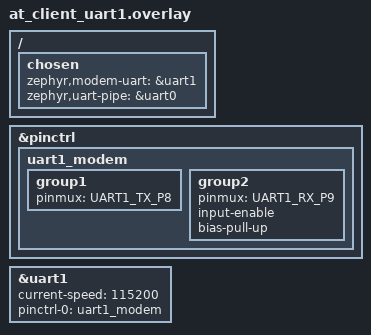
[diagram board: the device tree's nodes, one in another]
/* SPDX-License-Identifier: Apache-2.0 OR MIT */
/*
 * samples/drivers/modem/at_client bridges the console (uart0) to the modem
 * UART, which it takes from the zephyr,modem-uart chosen node: uart1 on the
 * straight-through pins, DUT TX GP8 and RX GP9, as the rig's uart1 images
 * (devices/neo_m8n/test/dut/uart1/rp2.overlay). RX is pulled up so the line
 * idles high before the harness attaches the modem part.
 */
/ {
	chosen {
		zephyr,modem-uart = &uart1;
		zephyr,uart-pipe = &uart0;
	};
};

&pinctrl {
	uart1_modem: uart1_modem {
		group1 {
			pinmux = <UART1_TX_P8>;
		};
		group2 {
			pinmux = <UART1_RX_P9>;
			input-enable;
			bias-pull-up;
		};
	};
};

&uart1 {
	status = "okay";
	current-speed = <115200>;
	pinctrl-0 = <&uart1_modem>;
	pinctrl-names = "default";
};
